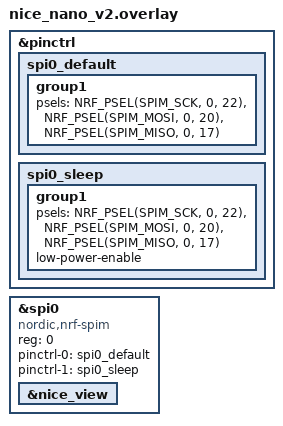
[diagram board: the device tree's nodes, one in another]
/*
 * Copyright (c) 2024 Noah Boggs 
 *
 * SPDX-License-Identifier: MIT
 */

// Configure pin assignments for spi0
&pinctrl {
    spi0_default: spi0_default {
        group1 {
            psels = <NRF_PSEL(SPIM_SCK, 0, 22)>,   // SCK pin (P0.22)
                    <NRF_PSEL(SPIM_MOSI, 0, 20)>,  // MOSI pin (P0.20)
                    <NRF_PSEL(SPIM_MISO, 0, 17)>;  // MISO pin (P0.17)
        };
    };

    spi0_sleep: spi0_sleep {
        group1 {
            psels = <NRF_PSEL(SPIM_SCK, 0, 22)>,   // SCK pin (P0.22)
                    <NRF_PSEL(SPIM_MOSI, 0, 20)>,  // MOSI pin (P0.20)
                    <NRF_PSEL(SPIM_MISO, 0, 17)>;  // MISO pin (P0.17)
            low-power-enable;
        };
    };
};

nice_view_spi: &spi0 {
    compatible = "nordic,nrf-spim";
    status = "okay";
    reg = <0>; // defined as @0 in the nice_view.overlay
    pinctrl-0 = <&spi0_default>;
    pinctrl-1 = <&spi0_sleep>;
    pinctrl-names = "default", "sleep";
    // cs-gpio is defined in _right.overlay

    &nice_view {
        status = "okay";
    };
};

